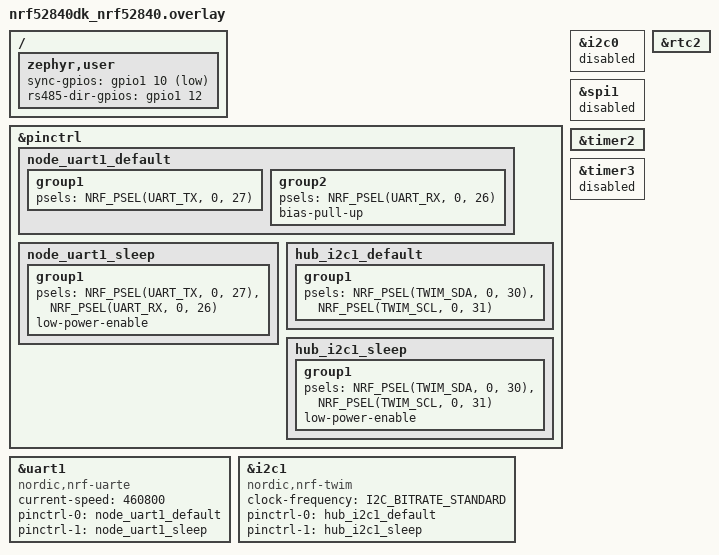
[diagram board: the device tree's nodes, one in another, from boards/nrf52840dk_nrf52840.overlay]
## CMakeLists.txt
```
cmake_minimum_required(VERSION 3.20.0)
find_package(Zephyr REQUIRED HINTS $ENV{ZEPHYR_BASE})

project(hub)

target_include_directories(app PRIVATE
  ${CMAKE_CURRENT_SOURCE_DIR}/../shared/include
  ${CMAKE_CURRENT_SOURCE_DIR}/src
)

target_sources(app PRIVATE
  src/main.cpp
  src/debug_log.cpp
  src/timebase.cpp
  src/controller_clock.cpp
  src/rs485_bus.cpp
  src/node_manager.cpp
  src/ble_gateway.cpp
  src/ttl_generator_manager.cpp
  src/experiment.cpp
  src/control.cpp
  src/local_sensors.cpp
  ../shared/src/sdc_anchor_report.c
  ../shared/src/transport.cpp
  ../shared/src/record_protocol.cpp
  ../shared/src/command_protocol.cpp
  ../shared/src/discovery_protocol.cpp
)

target_compile_options(app PRIVATE
  -Wall
  -Wextra
  -Wshadow
  $<$<COMPILE_LANGUAGE:CXX>:-fno-exceptions>
  $<$<COMPILE_LANGUAGE:CXX>:-fno-rtti>
)

if(DEFINED RIG_MAX_NODES)
  target_compile_definitions(app PRIVATE
    RIG_MAX_NODES=${RIG_MAX_NODES}
  )
endif()

if(DEFINED NODE_ENABLE_DEBUG_STREAM)
  target_compile_definitions(app PRIVATE
    NODE_ENABLE_DEBUG_STREAM=${NODE_ENABLE_DEBUG_STREAM}
  )
endif()
```

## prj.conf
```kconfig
CONFIG_CPP=y
CONFIG_STD_CPP17=y
CONFIG_GLIBCXX_LIBCPP=y

# ------------------------------------------------------------
# Console / USB CDC ACM
# ------------------------------------------------------------
CONFIG_SERIAL=y
CONFIG_CONSOLE=y
CONFIG_UART_CONSOLE=y
CONFIG_UART_LINE_CTRL=y
CONFIG_PRINTK=y
CONFIG_USB_DEVICE_STACK=y
CONFIG_USB_CDC_ACM=y
CONFIG_USB_DEVICE_INITIALIZE_AT_BOOT=y

# ------------------------------------------------------------
# Bluetooth
# ------------------------------------------------------------
CONFIG_BT=y
CONFIG_BT_CENTRAL=y
CONFIG_BT_PERIPHERAL=y
CONFIG_BT_DEVICE_NAME="Floating Hub"
CONFIG_BT_MAX_CONN=2
CONFIG_BT_GATT_CLIENT=y
CONFIG_BT_CTLR_SDC_PERIPHERAL_COUNT=1
CONFIG_BT_CTLR_SDC_CONN_ANCHOR_POINT_REPORT=y
CONFIG_BT_HCI_VS_EVT_USER=y
CONFIG_BT_RX_STACK_SIZE=6144
CONFIG_BT_L2CAP_TX_MTU=247
CONFIG_BT_BUF_ACL_RX_SIZE=251
CONFIG_BT_BUF_ACL_TX_SIZE=251
CONFIG_BT_BUF_ACL_TX_COUNT=16
CONFIG_BT_CTLR_DATA_LENGTH_MAX=251
CONFIG_BT_CTLR_PHY_2M=y
CONFIG_BT_USER_PHY_UPDATE=y
CONFIG_BT_USER_DATA_LEN_UPDATE=y
CONFIG_BT_BUF_EVT_RX_COUNT=17

# ------------------------------------------------------------
# Physical UART
#
# This is UART1 -> RS485 on the Floating Hub.
# USB CDC does NOT use UART1.
# ------------------------------------------------------------
CONFIG_UART_ASYNC_API=y
CONFIG_UART_1_INTERRUPT_DRIVEN=n
CONFIG_UART_1_ASYNC=y
# The RS485 receiver is always on, so low-power mode saves nothing. It also
# powers UARTE1 down and up on every error restart; the hub was seen wedged
# in that path (rx_disable accepted, RX_DISABLED never delivered, rx_enable
# then -EBUSY forever).
CONFIG_UART_1_NRF_ASYNC_LOW_POWER=n

# ------------------------------------------------------------
# I2C
# ------------------------------------------------------------
CONFIG_I2C=y

# ------------------------------------------------------------
# Host BLE link
# ------------------------------------------------------------
# Host is an interactive control and telemetry link.
# Ask the laptop central for a 7.5 to 15 ms interval with
# no peripheral latency.
CONFIG_BT_GAP_AUTO_UPDATE_CONN_PARAMS=y
CONFIG_BT_PERIPHERAL_PREF_MIN_INT=6
CONFIG_BT_PERIPHERAL_PREF_MAX_INT=12
CONFIG_BT_PERIPHERAL_PREF_LATENCY=0
CONFIG_BT_PERIPHERAL_PREF_TIMEOUT=200

# ------------------------------------------------------------
# Memory
# ------------------------------------------------------------
CONFIG_MAIN_STACK_SIZE=6144
CONFIG_SYSTEM_WORKQUEUE_STACK_SIZE=6144
CONFIG_HEAP_MEM_POOL_SIZE=4096

# ------------------------------------------------------------
# Debug
# ------------------------------------------------------------
CONFIG_ASSERT=y
CONFIG_LOG=n

# ------------------------------------------------------------
# GPIO / nrfx
# ------------------------------------------------------------
CONFIG_GPIO=n
CONFIG_NRFX_GPIOTE=y
CONFIG_NRFX_GPIOTE_NUM_OF_EVT_HANDLERS=2
CONFIG_NRFX_GPPI=y
CONFIG_NRFX_TIMER=y
CONFIG_NRFX_RTC=y

# ------------------------------------------------------------
# Clock
#
# Floating Hub does NOT have the BMD-340-EVAL carrier's
# external 32.768 kHz crystal.
# ------------------------------------------------------------
CONFIG_CLOCK_CONTROL=y
CONFIG_CLOCK_CONTROL_NRF=y
CONFIG_CLOCK_CONTROL_NRF_K32SRC_RC=y
CONFIG_CLOCK_CONTROL_NRF_K32SRC_500PPM=y
CONFIG_CLOCK_CONTROL_NRF_K32SRC_RC_CALIBRATION=y
```

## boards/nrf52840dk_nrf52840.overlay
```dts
#include <zephyr/dt-bindings/gpio/gpio.h>
#include <zephyr/dt-bindings/i2c/i2c.h>
#include <zephyr/dt-bindings/pinctrl/nrf-pinctrl.h>

/ {
    zephyr,user {
        sync-gpios = <&gpio1 10 GPIO_ACTIVE_LOW>;

        /*
         * The Grove RS-485 breakout used on the breadboard rig switches
         * direction automatically, so no DE line is wired. src/rs485_bus.cpp
         * requires this property unconditionally, so point it at a free,
         * unconnected DK pin. P1.12 is used by nothing else on this board.
         */
        rs485-dir-gpios = <&gpio1 12 GPIO_ACTIVE_HIGH>;
    };
};

&pinctrl {
    node_uart1_default: node_uart1_default {
        group1 {
            psels = <NRF_PSEL(UART_TX, 0, 27)>;
        };

        group2 {
            psels = <NRF_PSEL(UART_RX, 0, 26)>;
            bias-pull-up;
        };
    };

    node_uart1_sleep: node_uart1_sleep {
        group1 {
            psels = <NRF_PSEL(UART_TX, 0, 27)>,
                    <NRF_PSEL(UART_RX, 0, 26)>;
            low-power-enable;
        };
    };

    hub_i2c1_default: hub_i2c1_default {
        group1 {
            psels = <NRF_PSEL(TWIM_SDA, 0, 30)>,
                    <NRF_PSEL(TWIM_SCL, 0, 31)>;
        };
    };

    hub_i2c1_sleep: hub_i2c1_sleep {
        group1 {
            psels = <NRF_PSEL(TWIM_SDA, 0, 30)>,
                    <NRF_PSEL(TWIM_SCL, 0, 31)>;
            low-power-enable;
        };
    };
};

&uart1 {
    compatible = "nordic,nrf-uarte";
    status = "okay";
    current-speed = <460800>;
    pinctrl-0 = <&node_uart1_default>;
    pinctrl-1 = <&node_uart1_sleep>;
    pinctrl-names = "default", "sleep";
};

/*
 * The DK's normal i2c0 mapping uses P0.26/P0.27, which are already the
 * working node UART pins above. Keep that controller disabled.
 */
&i2c0 {
    status = "disabled";
};

/* i2c1 and spi1 share the same nRF peripheral instance on this DK. */
&spi1 {
    status = "disabled";
};

&i2c1 {
    compatible = "nordic,nrf-twim";
    status = "okay";
    clock-frequency = <I2C_BITRATE_STANDARD>;
    pinctrl-0 = <&hub_i2c1_default>;
    pinctrl-1 = <&hub_i2c1_sleep>;
    pinctrl-names = "default", "sleep";
};

&timer2 {
    status = "okay";
};

&timer3 {
    status = "disabled";
};

&rtc2 {
    status = "okay";
};
```

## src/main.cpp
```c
#include <zephyr/kernel.h>

#include "ble_gateway.hpp"
#include "control.hpp"
#include "debug_log.hpp"
#include "experiment.hpp"
#include "node_manager.hpp"
#include "ttl_generator_manager.hpp"
#include "local_sensors.hpp"
#include "rs485_bus.hpp"
#include "timebase.hpp"

namespace {

bool start_component(const char *name, int result) {
  hub_debug::log("START component=%s status=%d\r\n", name, result);
  return result == 0;
}

} // namespace

int main() {
  if (!start_component("timebase", hub_time::initialize()) ||
      !start_component("rs485", hub_rs485::initialize())) {
    return 1;
  }

  hub_ttl_generator::initialize();
  hub_control::initialize();
  hub_experiment::initialize();

  if (!start_component("nodes", hub_nodes::initialize()) ||
      !start_component("ble", hub_ble::initialize())) {
    return 1;
  }

  // Local sensors deliberately start after BLE so their node telemetry has a
  // transport available immediately. Sensor absence is reported as status and
  // does not make Hub unusable as a communications hub.
  if (!start_component("local_sensors", hub_local_sensors::initialize())) {
    return 1;
  }

  // D3 is driven by nPM1300 LED0 and is reserved as a trustworthy
  // firmware-owned "all startup stages completed" indicator.
  if (!hub_local_sensors::set_ready_led(true)) {
    hub_debug::log("READY_LED unavailable\r\n");
  }

  hub_debug::log(
      "READY transport=1 node=3 host=2 discovery=1 timer_hz=16000000 "
      "sync_hz=4\r\n");
  while (true) {
    k_sleep(K_SECONDS(60));
  }
  return 0;
}
```

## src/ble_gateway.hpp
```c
#pragma once

#include <cstddef>
#include <cstdint>

#include "rig_protocol/transport.hpp"

namespace hub_ble {

int initialize();

// Use diagnostic_priority for time-critical records. They share the
// reserved Host event queue and can preempt bulk telemetry between fragments.
bool send_to_host(std::uint8_t source, rig::transport::Channel channel,
                    const std::uint8_t *payload, std::size_t payload_length,
                    std::uint16_t transfer_id = 0, std::uint8_t flags = 0,
                    std::uint64_t command_receive_ticks = 0,
                    bool diagnostic_priority = false);

bool send_to_ttl_generator(rig::transport::Channel channel,
                       const std::uint8_t *payload, std::size_t payload_length,
                       std::uint16_t transfer_id = 0,
                       std::uint8_t flags = rig::transport::ack_required);

bool host_connected();
bool ttl_generator_connected();
std::int8_t ttl_generator_rssi();
std::uint32_t dropped_to_host();
std::uint32_t dropped_to_ttl_generator();

} // namespace hub_ble
```

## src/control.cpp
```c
#include "control.hpp"

#include <array>
#include <cstring>

#include <zephyr/kernel.h>
#include <zephyr/sys/atomic.h>

#include "ble_gateway.hpp"
#include "experiment.hpp"
#include "node_manager.hpp"
#include "rig_protocol/command_protocol.hpp"
#include "rig_protocol/record_protocol.hpp"
#include "rig_protocol/system_config.hpp"
#include "rig_protocol/tlv.hpp"
#include "ttl_generator_manager.hpp"
#include "local_sensors.hpp"
#include "rs485_bus.hpp"
#include "timebase.hpp"

namespace hub_control {
namespace {

inline constexpr std::uint32_t diagnostic_session = 0x53594E43U;

atomic_t session_id;
bool diagnostic_session_active;
k_mutex control_mutex;

bool command_u8(const rig::protocol::CommandMessageView &message,
                rig::protocol::CommandField wanted, std::uint8_t &value) {
  rig::protocol::TlvReader reader(message.payload,
                                    message.header.payload_length);
  rig::protocol::FieldView field;
  while (reader.next(field)) {
    if (field.tag == static_cast<std::uint16_t>(wanted)) {
      return rig::protocol::TlvReader::as_u8(field, value);
    }
  }
  return false;
}

bool command_u32(const rig::protocol::CommandMessageView &message,
                 rig::protocol::CommandField wanted, std::uint32_t &value) {
  rig::protocol::TlvReader reader(message.payload,
                                    message.header.payload_length);
  rig::protocol::FieldView field;
  while (reader.next(field)) {
    if (field.tag == static_cast<std::uint16_t>(wanted)) {
      return rig::protocol::TlvReader::as_u32(field, value);
    }
  }
  return false;
}

void send_response(const rig::protocol::CommandMessageView &command,
                   rig::protocol::Status status, std::uint16_t transfer_id,
                   const std::uint8_t *payload = nullptr,
                   std::size_t payload_length = 0,
                   std::uint64_t receive_ticks = 0) {
  rig::protocol::MessageHeader header = command.header;
  header.kind = rig::protocol::MessageKind::response;
  header.status = status;
  header.flags = 0;
  header.execute_at_ticks = 0;
  header.payload_length = 0;
  std::uint8_t response[rig::protocol::command_max_message_size]{};
  const std::size_t length = rig::protocol::encode_command(
      header, payload, payload_length, response, sizeof(response));
  if (length != 0U) {
    (void)hub_ble::send_to_host(rig::config::hub_address,
                                     rig::transport::Channel::command,
                                     response, length, transfer_id,
                                     rig::transport::response, receive_ticks);
  }
}

std::size_t make_session_command(rig::protocol::Opcode opcode,
                                 std::uint32_t session,
                                 std::uint8_t *destination,
                                 std::size_t capacity) {
  rig::protocol::MessageHeader header;
  header.opcode = opcode;
  header.flags =
      rig::protocol::require_response | rig::protocol::execute_immediately;
  header.command_id =
      static_cast<std::uint32_t>(hub_time::now() & 0xFFFF'FFFFULL);
  header.session_id = session;
  header.deadline_ms = 2000;
  return rig::protocol::encode_command(header, nullptr, 0, destination,
                                        capacity);
}

void propagate_session(rig::protocol::Opcode opcode, std::uint32_t session) {
  std::uint8_t message[rig::protocol::command_max_message_size]{};
  const std::size_t length =
      make_session_command(opcode, session, message, sizeof(message));
  if (length == 0U) {
    return;
  }
  hub_nodes::queue_command_for_all(message, length);
  (void)hub_ble::send_to_ttl_generator(rig::transport::Channel::command,
                                      message, length);
}

/* Node numbers are flashed into the boards, so every present node already
 * has its slot. Which nodes a session needs is Adelie's decision; the hub
 * only refuses a session with no nodes at all. */
bool any_node_present() { return hub_nodes::count() != 0U; }

rig::protocol::Status begin_session(std::uint32_t wanted,
                                      bool require_synchronization) {
  if (wanted == 0U || !any_node_present()) {
    return wanted == 0U ? rig::protocol::Status::invalid_parameter
                        : rig::protocol::Status::inventory_mismatch;
  }
  if (!hub_ble::ttl_generator_connected()) {
    return rig::protocol::Status::transport_error;
  }
  if (require_synchronization) {
    for (std::size_t index = 0; index < hub_nodes::count(); ++index) {
      hub_nodes::NodeSnapshot node;
      if (!hub_nodes::snapshot(index, node) || !node.synchronized) {
        return rig::protocol::Status::not_synchronized;
      }
    }
    if (!hub_ttl_generator::quality().valid) {
      return rig::protocol::Status::not_synchronized;
    }
  }
  const std::uint32_t current =
      static_cast<std::uint32_t>(atomic_get(&session_id));
  if (current != 0U && current != wanted) {
    return rig::protocol::Status::busy;
  }
  atomic_set(&session_id, static_cast<atomic_val_t>(wanted));
  hub_experiment::set_session(wanted);
  hub_local_sensors::set_session(wanted);
  propagate_session(rig::protocol::Opcode::start_session, wanted);
  return rig::protocol::Status::accepted;
}

void end_session(std::uint32_t ended) {
  hub_experiment::stop_sync_test();
  hub_experiment::stop_ttl_train();
  propagate_session(rig::protocol::Opcode::stop_session, ended);
  hub_experiment::set_session(0);
  hub_local_sensors::set_session(0);
  atomic_clear(&session_id);
  diagnostic_session_active = false;
}

void handle_local(const rig::protocol::CommandMessageView &command,
                  std::uint16_t transfer_id, std::uint64_t receive_ticks) {
  rig::protocol::Status status = rig::protocol::Status::ok;
  std::uint8_t response_payload[rig::protocol::command_max_payload]{};
  rig::protocol::TlvWriter response_fields(response_payload,
                                             sizeof(response_payload));

  switch (command.header.opcode) {
  case rig::protocol::Opcode::ping:
    break;

  case rig::protocol::Opcode::get_inventory: {
    std::uint8_t inventory[rig::config::max_nodes * 18U]{};
    const std::size_t length =
        hub_nodes::inventory_bytes(inventory, sizeof(inventory));
    if (length != 0U) {
      (void)response_fields.bytes(
          static_cast<std::uint16_t>(rig::protocol::CommandField::uuid_list),
          inventory, static_cast<std::uint8_t>(length));
    }
    break;
  }

  case rig::protocol::Opcode::get_health: {
    (void)response_fields.u32(
        static_cast<std::uint16_t>(rig::protocol::Field::transport_errors),
        hub_rs485::errors());
    (void)response_fields.u32(
        static_cast<std::uint16_t>(rig::protocol::Field::retry_count),
        hub_rs485::retries());
    (void)response_fields.i32(
        static_cast<std::uint16_t>(rig::protocol::Field::rssi_dbm),
        hub_ble::ttl_generator_rssi());
    (void)response_fields.u8(
        static_cast<std::uint16_t>(rig::protocol::Field::state),
        hub_ble::ttl_generator_connected() ? 1U : 0U);
    const auto sensors = hub_local_sensors::snapshot();
    (void)response_fields.u8(
        static_cast<std::uint16_t>(rig::protocol::Field::sensor_status),
        sensors.status);
    (void)response_fields.u32(
        static_cast<std::uint16_t>(rig::protocol::Field::sample_count),
        sensors.sample_count);
    (void)response_fields.u32(
        static_cast<std::uint16_t>(rig::protocol::Field::sensor_i2c_errors),
        sensors.i2c_errors);
    break;
  }

  case rig::protocol::Opcode::set_telemetry: {
    std::uint8_t raw{};
    if (!command_u8(command, rig::protocol::CommandField::telemetry_level,
                    raw) ||
        raw >
            static_cast<std::uint8_t>(rig::protocol::TelemetryLevel::full)) {
      status = rig::protocol::Status::invalid_parameter;
    } else {
      const auto level = static_cast<rig::protocol::TelemetryLevel>(raw);
      hub_nodes::set_telemetry(level);
      hub_local_sensors::set_telemetry(level);
    }
    break;
  }

  case rig::protocol::Opcode::set_status_led: {
    std::uint8_t led_index{};
    std::uint8_t enabled{};
    if (!command_u8(command, rig::protocol::CommandField::led_index,
                    led_index) ||
        !command_u8(command, rig::protocol::CommandField::enabled, enabled) ||
        led_index < 1U || led_index > 2U || enabled > 1U) {
      status = rig::protocol::Status::invalid_parameter;
    } else {
      // Protocol/UI uses schematic labels D1/D2. Hardware channels are
      // D1 -> nPM LED2 and D2 -> nPM LED1. D3/nPM LED0 is reserved READY.
      const std::uint8_t pmic_led_index = 3U - led_index;
      if (!hub_local_sensors::set_status_led(pmic_led_index,
                                                 enabled != 0U)) {
        status = rig::protocol::Status::invalid_state;
      }
    }
    break;
  }

  case rig::protocol::Opcode::clock_exchange:
    (void)response_fields.u64(
        static_cast<std::uint16_t>(
            rig::protocol::CommandField::clock_t2_ticks),
        receive_ticks);
    (void)response_fields.u64(
        static_cast<std::uint16_t>(
            rig::protocol::CommandField::clock_t3_ticks),
        hub_time::now());
    break;

  case rig::protocol::Opcode::start_session:
    status = begin_session(command.header.session_id, true);
    break;

  case rig::protocol::Opcode::stop_session: {
    const std::uint32_t current =
        static_cast<std::uint32_t>(atomic_get(&session_id));
    if (current != 0U && command.header.session_id != current) {
      status = rig::protocol::Status::session_mismatch;
    } else if (current != 0U) {
      end_session(current);
    }
    break;
  }

  case rig::protocol::Opcode::start_ttl_train: {
    std::uint32_t frequency{};
    std::uint32_t width{};
    std::uint32_t count{};
    if (!command_u32(command,
                     rig::protocol::CommandField::ttl_frequency_millihz,
                     frequency) ||
        !command_u32(command, rig::protocol::CommandField::ttl_width_us,
                     width)) {
      status = rig::protocol::Status::invalid_parameter;
    } else {
      (void)command_u32(command, rig::protocol::CommandField::ttl_count,
                        count);
      bool opened_diagnostic_session = false;
      if (atomic_get(&session_id) == 0) {
        status = begin_session(diagnostic_session, false);
        opened_diagnostic_session = status == rig::protocol::Status::accepted;
        if (opened_diagnostic_session) {
          diagnostic_session_active = true;
        }
      }
      if (status == rig::protocol::Status::ok ||
          status == rig::protocol::Status::accepted) {
        if (hub_experiment::start_ttl_train(frequency, width, count)) {
          status = rig::protocol::Status::accepted;
        } else {
          status = rig::protocol::Status::invalid_state;
          if (opened_diagnostic_session) {
            end_session(diagnostic_session);
          }
        }
      }
    }
    break;
  }

  case rig::protocol::Opcode::stop_ttl_train:
    hub_experiment::stop_ttl_train();
    if (diagnostic_session_active && !hub_experiment::sync_test_active()) {
      end_session(diagnostic_session);
    }
    break;

  case rig::protocol::Opcode::start_sync_test: {
    std::uint32_t interval = 5000;
    std::uint32_t width = 100;
    (void)command_u32(command,
                      rig::protocol::CommandField::test_command_interval_ms,
                      interval);
    (void)command_u32(command, rig::protocol::CommandField::ttl_width_us,
                      width);
    if (atomic_get(&session_id) == 0) {
      status = begin_session(diagnostic_session, false);
      diagnostic_session_active = status == rig::protocol::Status::accepted;
    }
    if ((status == rig::protocol::Status::ok ||
         status == rig::protocol::Status::accepted) &&
        !hub_experiment::start_sync_test(interval, width)) {
      status = rig::protocol::Status::invalid_parameter;
    } else if (status == rig::protocol::Status::ok) {
      status = rig::protocol::Status::accepted;
    }
    break;
  }

  case rig::protocol::Opcode::stop_sync_test:
    hub_experiment::stop_sync_test();
    if (diagnostic_session_active) {
      end_session(diagnostic_session);
    }
    break;

  default:
    status = rig::protocol::Status::unsupported;
    break;
  }

  send_response(command, status, transfer_id, response_payload,
                response_fields.size(), receive_ticks);
}

} // namespace

void initialize() {
  k_mutex_init(&control_mutex);
  atomic_clear(&session_id);
  diagnostic_session_active = false;
}

void receive_from_host(const rig::transport::MessageView &message,
                         std::uint64_t receive_ticks) {
  rig::protocol::CommandMessageView command;
  if (!rig::protocol::decode_command(message.payload, message.payload_length,
                                      command) ||
      command.header.kind != rig::protocol::MessageKind::command) {
    return;
  }

  k_mutex_lock(&control_mutex, K_FOREVER);
  if (message.destination == rig::config::hub_address) {
    handle_local(command, message.transfer_id, receive_ticks);
  } else if (message.destination == rig::config::ttl_generator_address) {
    if (!hub_ble::send_to_ttl_generator(rig::transport::Channel::command,
                                       message.payload, message.payload_length,
                                       message.transfer_id, message.flags)) {
      send_response(command, rig::protocol::Status::transport_error,
                    message.transfer_id, nullptr, 0, receive_ticks);
    }
  } else if (rig::config::is_node_address(message.destination)) {
    if (!hub_nodes::queue_command(message.destination, message.payload,
                                       message.payload_length,
                                       message.transfer_id)) {
      send_response(command, rig::protocol::Status::queue_full,
                    message.transfer_id, nullptr, 0, receive_ticks);
    }
  } else if (message.destination == rig::config::broadcast_address) {
    hub_nodes::queue_command_for_all(message.payload,
                                          message.payload_length);
    (void)hub_ble::send_to_ttl_generator(rig::transport::Channel::command,
                                        message.payload,
                                        message.payload_length);
    send_response(command, rig::protocol::Status::accepted,
                  message.transfer_id, nullptr, 0, receive_ticks);
  } else {
    send_response(command, rig::protocol::Status::invalid_parameter,
                  message.transfer_id, nullptr, 0, receive_ticks);
  }
  k_mutex_unlock(&control_mutex);
}

void host_disconnected() {
  k_mutex_lock(&control_mutex, K_FOREVER);
  const std::uint32_t current =
      static_cast<std::uint32_t>(atomic_get(&session_id));
  if (current != 0U) {
    end_session(current);
  }
  k_mutex_unlock(&control_mutex);
}

void dependency_disconnected(const char *reason) {
  k_mutex_lock(&control_mutex, K_FOREVER);
  const std::uint32_t current =
      static_cast<std::uint32_t>(atomic_get(&session_id));
  if (current != 0U) {
    hub_experiment::publish_fault(reason);
    end_session(current);
  }
  k_mutex_unlock(&control_mutex);
}

std::uint32_t active_session() {
  return static_cast<std::uint32_t>(atomic_get(&session_id));
}

} // namespace hub_control
```

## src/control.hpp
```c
#pragma once

#include <cstdint>

#include "rig_protocol/transport.hpp"

namespace hub_control {

void initialize();
void receive_from_host(const rig::transport::MessageView &message,
                         std::uint64_t receive_ticks);
void host_disconnected();
void dependency_disconnected(const char *reason);
std::uint32_t active_session();

} // namespace hub_control
```

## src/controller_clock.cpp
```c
#include "controller_clock.hpp"

#include <cerrno>

#include <hal/nrf_rtc.h>
#include <nrfx_rtc.h>

#include <zephyr/irq.h>
#include <zephyr/kernel.h>
#include <zephyr/sys/barrier.h>

#include "debug_log.hpp"
#include "timebase.hpp"

namespace hub_controller_clock {
namespace {

inline constexpr std::uint64_t rtc_tick_femtoseconds = 30'517'578'125ULL;
inline constexpr std::uint64_t rtc_overflow_us = 512'000'000ULL;

nrfx_rtc_t application_rtc = NRFX_RTC_INSTANCE(NRF_RTC_INST_GET(2));
volatile std::uint32_t rtc_overflows;
std::int32_t controller_offset;
rig::time::AffineClockModel<16> bridge;
k_mutex bridge_mutex;
K_SEM_DEFINE(start_sem, 0, 1);

std::uint64_t rtc_to_us(std::uint32_t ticks) {
  return static_cast<std::uint64_t>(ticks) * rtc_tick_femtoseconds /
         1'000'000'000ULL;
}

void rtc_handler(nrf_rtc_event_t event, void *) {
  if (event == NRF_RTC_EVENT_OVERFLOW) {
    ++rtc_overflows;
  }
}

std::int32_t measure_offset() {
  std::uint32_t difference = (nrf_rtc_counter_get(NRF_RTC0) -
                              nrf_rtc_counter_get(application_rtc.p_reg)) &
                             0x00FF'FFFFU;
  if ((difference & 0x0080'0000U) != 0U) {
    difference |= 0xFF00'0000U;
  }
  return static_cast<std::int32_t>(difference);
}

std::uint64_t controller_us() {
  std::uint32_t overflows;
  std::uint32_t ticks;
  do {
    overflows = rtc_overflows;
    barrier_isync_fence_full();
    ticks = nrf_rtc_counter_get(application_rtc.p_reg);
    barrier_isync_fence_full();
  } while (overflows != rtc_overflows);
  const std::int64_t base =
      static_cast<std::int64_t>(rtc_to_us(ticks)) +
      static_cast<std::int64_t>(overflows * rtc_overflow_us);
  const std::int64_t offset_us =
      static_cast<std::int64_t>(controller_offset) *
      static_cast<std::int64_t>(rtc_tick_femtoseconds) / 1'000'000'000LL;
  const std::int64_t result = base + offset_us;
  return result < 0 ? 0U : static_cast<std::uint64_t>(result);
}

void sample_thread(void *, void *, void *) {
  k_sem_take(&start_sem, K_FOREVER);
  while (true) {
    k_sleep(K_MSEC(250));
    const std::uint64_t before = hub_time::now();
    const std::uint64_t controller_ticks = controller_us() * 16ULL;
    const std::uint64_t after = hub_time::now();
    if (after < before || after - before > 32'000ULL) {
      continue;
    }
    const std::uint64_t midpoint = before + (after - before) / 2ULL;
    k_mutex_lock(&bridge_mutex, K_FOREVER);
    (void)bridge.add(controller_ticks, midpoint);
    k_mutex_unlock(&bridge_mutex);
  }
}

K_THREAD_DEFINE(sample_thread_id, 1536, sample_thread, nullptr, nullptr,
                nullptr, 8, 0, 0);

} // namespace

int initialize() {
  k_mutex_init(&bridge_mutex);
  bridge.set_admission(3200.0, 6.0, 3);
  nrfx_rtc_config_t config = NRFX_RTC_DEFAULT_CONFIG;
  int error = nrfx_rtc_init(&application_rtc, &config, rtc_handler);
  if (error != 0) {
    return error;
  }
  IRQ_CONNECT(NRFX_IRQ_NUMBER_GET(NRF_RTC_INST_GET(2)), IRQ_PRIO_LOWEST,
              nrfx_rtc_irq_handler, &application_rtc, 0);
  nrfx_rtc_overflow_enable(&application_rtc, true);
  nrfx_rtc_tick_enable(&application_rtc, false);
  nrfx_rtc_enable(&application_rtc);

  for (unsigned int attempt = 0; attempt < 10; ++attempt) {
    const std::int32_t first = measure_offset();
    k_busy_wait(15);
    const std::int32_t second = measure_offset();
    if (first == second) {
      controller_offset = first;
      k_sem_give(&start_sem);
      return 0;
    }
  }
  return -EIO;
}

bool to_hub(std::uint64_t controller_ticks, std::uint64_t &hub_ticks) {
  const std::uint64_t raw_us = controller_ticks / 16ULL;
  const std::uint64_t near_us = controller_us();
  std::uint64_t extended_us =
      (near_us & ~0xFFFF'FFFFULL) | (raw_us & 0xFFFF'FFFFULL);
  if (extended_us + 0x8000'0000ULL < near_us) {
    extended_us += 0x1'0000'0000ULL;
  } else if (extended_us > near_us + 0x8000'0000ULL &&
             extended_us >= 0x1'0000'0000ULL) {
    extended_us -= 0x1'0000'0000ULL;
  }
  k_mutex_lock(&bridge_mutex, K_FOREVER);
  const bool result = bridge.predict(extended_us * 16ULL, hub_ticks);
  k_mutex_unlock(&bridge_mutex);
  return result;
}

rig::time::ClockQuality quality() {
  k_mutex_lock(&bridge_mutex, K_FOREVER);
  const auto result = bridge.quality();
  k_mutex_unlock(&bridge_mutex);
  return result;
}

} // namespace hub_controller_clock
```

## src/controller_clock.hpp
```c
#pragma once

#include <cstdint>

#include "rig_protocol/clock_model.hpp"

namespace hub_controller_clock {

int initialize();
bool to_hub(std::uint64_t controller_ticks, std::uint64_t &hub_ticks);
rig::time::ClockQuality quality();

} // namespace hub_controller_clock
```

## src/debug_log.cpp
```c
#include "debug_log.hpp"

#include <cstdarg>

#include <zephyr/kernel.h>
#include <zephyr/sys/printk.h>

#include "rig_protocol/system_config.hpp"

namespace hub_debug {
namespace {

struct Line {
  char text[224];
};

K_MSGQ_DEFINE(lines, sizeof(Line), 24, 4);

void thread(void *, void *, void *) {
  Line line;
  while (true) {
    k_msgq_get(&lines, &line, K_FOREVER);
#if NODE_ENABLE_DEBUG_STREAM
    printk("%s", line.text);
#endif
  }
}

K_THREAD_DEFINE(debug_thread_id, 1536, thread, nullptr, nullptr, nullptr, 10, 0,
                0);

} // namespace

void log(const char *format, ...) {
#if NODE_ENABLE_DEBUG_STREAM
  Line line{};
  va_list arguments;
  va_start(arguments, format);
  const int length = vsnprintk(line.text, sizeof(line.text), format, arguments);
  va_end(arguments);
  if (length > 0 && length < static_cast<int>(sizeof(line.text))) {
    (void)k_msgq_put(&lines, &line, K_NO_WAIT);
  }
#else
  (void)format;
#endif
}

} // namespace hub_debug
```

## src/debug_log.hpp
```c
#pragma once

namespace hub_debug {

void log(const char *format, ...);

} // namespace hub_debug
```

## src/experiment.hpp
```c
#pragma once

#include <cstdint>

#include "rig_protocol/command_protocol.hpp"

namespace hub_experiment {

void initialize();
void host_connected();
void publish_fault(const char *reason);
void set_session(std::uint32_t session_id);

bool start_ttl_train(std::uint32_t frequency_millihz, std::uint32_t width_us,
                     std::uint32_t count);
void stop_ttl_train();

bool start_sync_test(std::uint32_t command_interval_ms, std::uint32_t width_us);
void stop_sync_test();
bool sync_test_active();

void note_ttl_generator_ttl(std::uint32_t sequence,
                        std::uint64_t local_actual_ticks,
                        std::uint64_t hub_actual_ticks);
void note_ttl_generator_ttl_status(std::uint32_t sequence,
                               rig::protocol::Status status);

void record_transport_timing(std::uint16_t transfer_id,
                             std::uint32_t command_id, std::uint16_t operation,
                             std::uint64_t receive_ticks,
                             std::uint64_t queued_ticks,
                             std::uint64_t transmit_start_ticks,
                             std::uint64_t transmit_complete_ticks,
                             std::uint16_t fragment_count,
                             std::uint16_t att_mtu);

} // namespace hub_experiment
```

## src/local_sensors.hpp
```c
#pragma once

#include <cstdint>

#include "rig_protocol/record_protocol.hpp"

namespace hub_local_sensors {

// Status bit mask used by Field::sensor_status.
inline constexpr std::uint8_t status_i2c_ready = 1U << 0U;
inline constexpr std::uint8_t status_imu_present = 1U << 1U;
inline constexpr std::uint8_t status_magnetometer_present = 1U << 2U;
inline constexpr std::uint8_t status_pmic_present = 1U << 3U;

struct Snapshot {
  std::uint8_t status{};
  std::uint32_t sample_count{};
  std::uint32_t i2c_errors{};
  bool vbus_present{};
  std::uint16_t battery_millivolts{};
  std::int32_t battery_current_ma{};
  bool battery_current_valid{};
  std::uint8_t charger_status{};
  std::uint8_t charger_error_reason{};
  std::uint8_t charger_error_sensor{};
  std::int32_t accel_mg[3]{};
  std::int32_t gyro_mdps[3]{};
  std::int32_t mag_milligauss[3]{};
};

// Starts the local I2C sensor worker. Missing sensors are reported in telemetry
// but do not prevent the rest of the hub from starting.
int initialize();

void set_telemetry(rig::protocol::TelemetryLevel level);
void set_session(std::uint32_t session_id);

// Schematic D3 is nPM1300 LED0 and is reserved for the hub READY.
// Schematic D1/D2 are nPM1300 LED2/LED1 and are user-programmable.
bool set_ready_led(bool enabled);
bool set_status_led(std::uint8_t led_index, bool enabled);

Snapshot snapshot();

} // namespace hub_local_sensors
```
